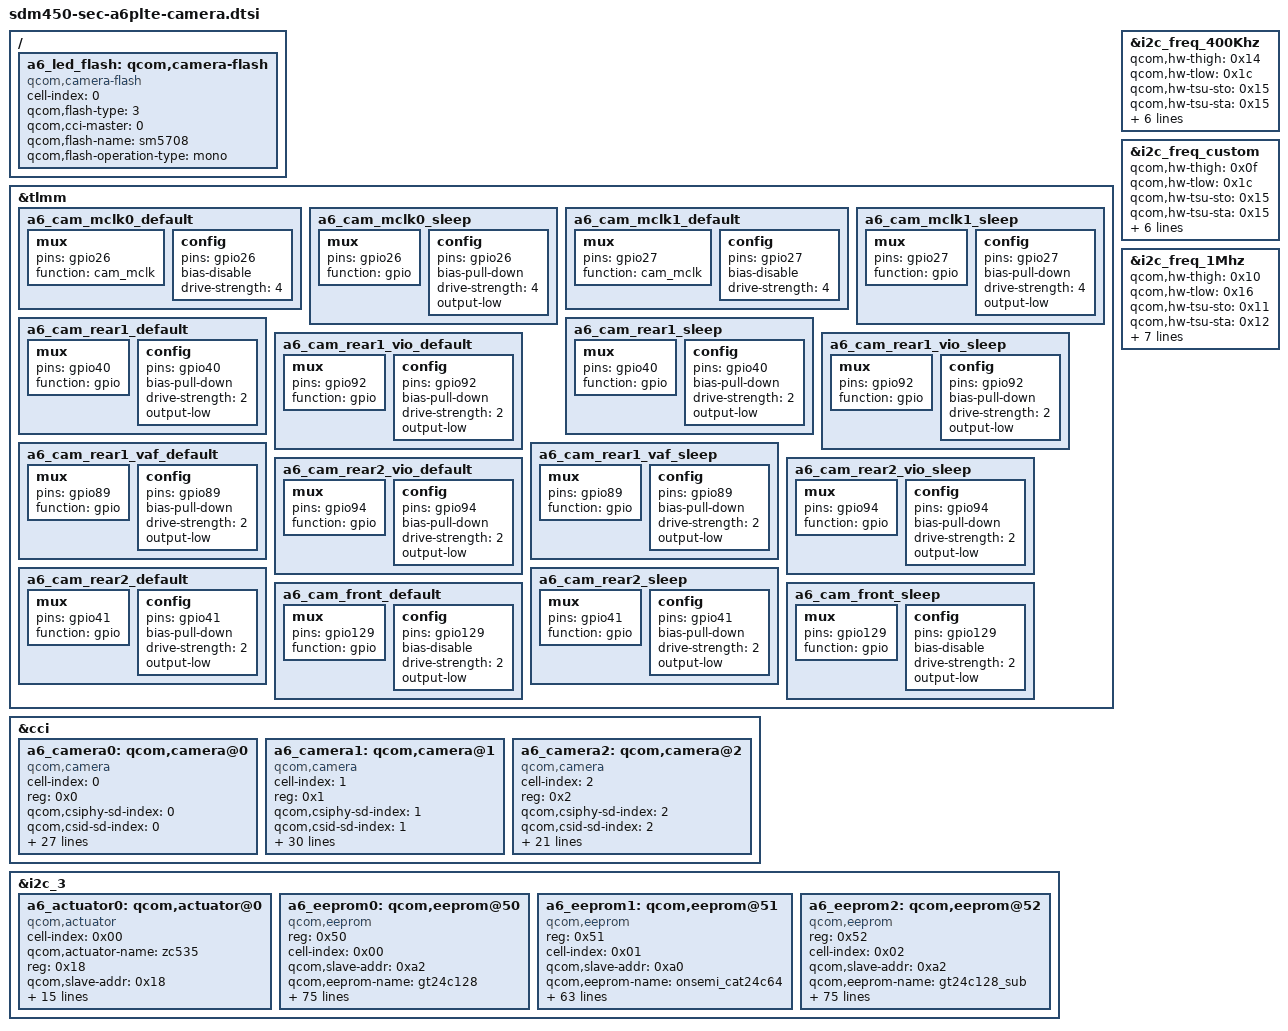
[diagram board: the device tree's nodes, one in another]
// Camera of the Samsung A6+ (rear S5K2P6SX, front S5K2X7SP, second rear SR556).
// Generated by scripts/gen-a6plte-camera-dtsi.py from the stock device tree.

&tlmm {
	a6_cam_mclk0_default: a6_cam_mclk0_default {
		mux {
			pins = "gpio26";
			function = "cam_mclk";
		};
		config {
			pins = "gpio26";
			bias-disable;
			drive-strength = <4>;
		};
	};

	a6_cam_mclk0_sleep: a6_cam_mclk0_sleep {
		mux {
			pins = "gpio26";
			function = "gpio";
		};
		config {
			pins = "gpio26";
			bias-pull-down;
			drive-strength = <4>;
			output-low;
		};
	};

	a6_cam_mclk1_default: a6_cam_mclk1_default {
		mux {
			pins = "gpio27";
			function = "cam_mclk";
		};
		config {
			pins = "gpio27";
			bias-disable;
			drive-strength = <4>;
		};
	};

	a6_cam_mclk1_sleep: a6_cam_mclk1_sleep {
		mux {
			pins = "gpio27";
			function = "gpio";
		};
		config {
			pins = "gpio27";
			bias-pull-down;
			drive-strength = <4>;
			output-low;
		};
	};

	a6_cam_rear1_default: a6_cam_rear1_default {
		mux {
			pins = "gpio40";
			function = "gpio";
		};
		config {
			pins = "gpio40";
			bias-pull-down;
			drive-strength = <2>;
			output-low;
		};
	};

	a6_cam_rear1_sleep: a6_cam_rear1_sleep {
		mux {
			pins = "gpio40";
			function = "gpio";
		};
		config {
			pins = "gpio40";
			bias-pull-down;
			drive-strength = <2>;
			output-low;
		};
	};

	a6_cam_rear1_vio_default: a6_cam_rear1_vio_default {
		mux {
			pins = "gpio92";
			function = "gpio";
		};
		config {
			pins = "gpio92";
			bias-pull-down;
			drive-strength = <2>;
			output-low;
		};
	};

	a6_cam_rear1_vio_sleep: a6_cam_rear1_vio_sleep {
		mux {
			pins = "gpio92";
			function = "gpio";
		};
		config {
			pins = "gpio92";
			bias-pull-down;
			drive-strength = <2>;
			output-low;
		};
	};

	a6_cam_rear1_vaf_default: a6_cam_rear1_vaf_default {
		mux {
			pins = "gpio89";
			function = "gpio";
		};
		config {
			pins = "gpio89";
			bias-pull-down;
			drive-strength = <2>;
			output-low;
		};
	};

	a6_cam_rear1_vaf_sleep: a6_cam_rear1_vaf_sleep {
		mux {
			pins = "gpio89";
			function = "gpio";
		};
		config {
			pins = "gpio89";
			bias-pull-down;
			drive-strength = <2>;
			output-low;
		};
	};

	a6_cam_rear2_vio_default: a6_cam_rear2_vio_default {
		mux {
			pins = "gpio94";
			function = "gpio";
		};
		config {
			pins = "gpio94";
			bias-pull-down;
			drive-strength = <2>;
			output-low;
		};
	};

	a6_cam_rear2_vio_sleep: a6_cam_rear2_vio_sleep {
		mux {
			pins = "gpio94";
			function = "gpio";
		};
		config {
			pins = "gpio94";
			bias-pull-down;
			drive-strength = <2>;
			output-low;
		};
	};

	a6_cam_rear2_default: a6_cam_rear2_default {
		mux {
			pins = "gpio41";
			function = "gpio";
		};
		config {
			pins = "gpio41";
			bias-pull-down;
			drive-strength = <2>;
			output-low;
		};
	};

	a6_cam_rear2_sleep: a6_cam_rear2_sleep {
		mux {
			pins = "gpio41";
			function = "gpio";
		};
		config {
			pins = "gpio41";
			bias-pull-down;
			drive-strength = <2>;
			output-low;
		};
	};

	a6_cam_front_default: a6_cam_front_default {
		mux {
			pins = "gpio129";
			function = "gpio";
		};
		config {
			pins = "gpio129";
			bias-disable;
			drive-strength = <2>;
			output-low;
		};
	};

	a6_cam_front_sleep: a6_cam_front_sleep {
		mux {
			pins = "gpio129";
			function = "gpio";
		};
		config {
			pins = "gpio129";
			bias-disable;
			drive-strength = <2>;
			output-low;
		};
	};

};

&cci {
	#address-cells = <1>;
	#size-cells = <0>;

	/* CCI timings of the stock DT (standard mode stays unused) */
}; /* cci */

&i2c_freq_400Khz {
	status = "ok";
	qcom,hw-thigh = <0x14>;
	qcom,hw-tlow = <0x1c>;
	qcom,hw-tsu-sto = <0x15>;
	qcom,hw-tsu-sta = <0x15>;
	qcom,hw-thd-dat = <0x0d>;
	qcom,hw-thd-sta = <0x12>;
	qcom,hw-tbuf = <0x20>;
	qcom,hw-scl-stretch-en = <0x00>;
	qcom,hw-trdhld = <0x06>;
	qcom,hw-tsp = <0x03>;
};

&i2c_freq_custom {
	status = "ok";
	qcom,hw-thigh = <0x0f>;
	qcom,hw-tlow = <0x1c>;
	qcom,hw-tsu-sto = <0x15>;
	qcom,hw-tsu-sta = <0x15>;
	qcom,hw-thd-dat = <0x0d>;
	qcom,hw-thd-sta = <0x12>;
	qcom,hw-tbuf = <0x19>;
	qcom,hw-scl-stretch-en = <0x01>;
	qcom,hw-trdhld = <0x06>;
	qcom,hw-tsp = <0x03>;
};

&i2c_freq_1Mhz {
	status = "ok";
	qcom,hw-thigh = <0x10>;
	qcom,hw-tlow = <0x16>;
	qcom,hw-tsu-sto = <0x11>;
	qcom,hw-tsu-sta = <0x12>;
	qcom,hw-thd-dat = <0x10>;
	qcom,hw-thd-sta = <0x0f>;
	qcom,hw-tbuf = <0x13>;
	qcom,hw-scl-stretch-en = <0x01>;
	qcom,hw-trdhld = <0x03>;
	qcom,hw-tsp = <0x03>;
	qcom,cci-clk-src = <0x23c3460>;
};

&i2c_3 {
	status = "ok";

	a6_actuator0: qcom,actuator@0 {
		compatible = "qcom,actuator";
		cell-index = <0x00>;
		qcom,actuator-name = "zc535";
		reg = <0x18>;
		qcom,slave-addr = <0x18>;
		gpios = <&tlmm 92 0>, <&tlmm 89 0>, <&expander 12 0>;
		qcom,gpio-vio = <0x00>;
		qcom,gpio-vaf = <0x01>;
		qcom,gpio-custom1 = <0x02>;
		qcom,gpio-req-tbl-num = <0x00 0x01 0x02>;
		qcom,gpio-req-tbl-flags = <0x00 0x00 0x00>;
		qcom,gpio-req-tbl-label = "CAM_VIO", "CAM_VAF", "CAM_CUSTOM1";
		qcom,sensor-position = <0x00>;
		qcom,cam-power-seq-type = "sensor_gpio", "sensor_gpio", "sensor_gpio";
		qcom,cam-power-seq-val = "sensor_gpio_vio", "sensor_gpio_vaf", "sensor_gpio_custom1";
		qcom,cam-power-seq-cfg-val = <0x01 0x01 0x01>;
		qcom,cam-power-seq-delay = <0x02 0x02 0x02>;
	};

	a6_eeprom0: qcom,eeprom@50 {
		compatible = "qcom,eeprom";
		reg = <0x50>;
		cell-index = <0x00>;
		qcom,slave-addr = <0xa2>;
		qcom,eeprom-name = "gt24c128";
		pinctrl-names = "cam_default", "cam_suspend";
		pinctrl-0 = <&a6_cam_rear1_vio_default &a6_cam_rear1_vaf_default>;
		pinctrl-1 = <&a6_cam_rear1_vio_sleep &a6_cam_rear1_vaf_sleep>;
		gpios = <&tlmm 92 0>, <&tlmm 89 0>, <&expander 12 0>;
		qcom,gpio-vio = <0x00>;
		qcom,gpio-vaf = <0x01>;
		qcom,gpio-custom1 = <0x02>;
		qcom,gpio-req-tbl-num = <0x00 0x01 0x02>;
		qcom,gpio-req-tbl-flags = <0x00 0x00 0x00>;
		qcom,gpio-req-tbl-label = "CAM_VIO", "CAM_VAF", "CAM_CUSTOM1";
		qcom,sensor-position = <0x00>;
		qcom,cam-power-seq-type = "sensor_gpio", "sensor_gpio", "sensor_gpio";
		qcom,cam-power-seq-val = "sensor_gpio_vio", "sensor_gpio_vaf", "sensor_gpio_custom1";
		qcom,cam-power-seq-cfg-val = <0x01 0x01 0x01>;
		qcom,cam-power-seq-delay = <0x02 0x02 0x02>;
		qcom,num-blocks = <0x12>;
		qcom,page0 = <0x00 0x00 0x00 0x00 0x00 0x00>;
		qcom,poll0 = <0x00 0x00 0x00 0x00 0x00 0x00>;
		qcom,mem0 = <0xfc 0x00 0x02 0x00 0x01 0x00>;
		qcom,page1 = <0x00 0x00 0x00 0x00 0x00 0x00>;
		qcom,poll1 = <0x00 0x00 0x00 0x00 0x00 0x00>;
		qcom,mem1 = <0x04 0xfc 0x02 0x00 0x01 0x00>;
		qcom,page2 = <0x00 0x00 0x00 0x00 0x00 0x00>;
		qcom,poll2 = <0x00 0x00 0x00 0x00 0x00 0x00>;
		qcom,mem2 = <0x708 0x100 0x02 0x00 0x01 0x00>;
		qcom,page3 = <0x00 0x00 0x00 0x00 0x00 0x00>;
		qcom,poll3 = <0x00 0x00 0x00 0x00 0x00 0x00>;
		qcom,mem3 = <0x04 0x808 0x02 0x00 0x01 0x00>;
		qcom,page4 = <0x00 0x00 0x00 0x00 0x00 0x00>;
		qcom,poll4 = <0x00 0x00 0x00 0x00 0x00 0x00>;
		qcom,mem4 = <0x50 0x80c 0x02 0x00 0x01 0x00>;
		qcom,page5 = <0x00 0x00 0x00 0x00 0x00 0x00>;
		qcom,poll5 = <0x00 0x00 0x00 0x00 0x00 0x00>;
		qcom,mem5 = <0x04 0x85c 0x02 0x00 0x01 0x00>;
		qcom,page6 = <0x00 0x00 0x00 0x00 0x00 0x00>;
		qcom,poll6 = <0x00 0x00 0x00 0x00 0x00 0x00>;
		qcom,mem6 = <0x30 0x860 0x02 0x00 0x01 0x00>;
		qcom,page7 = <0x00 0x00 0x00 0x00 0x00 0x00>;
		qcom,poll7 = <0x00 0x00 0x00 0x00 0x00 0x00>;
		qcom,mem7 = <0x04 0x890 0x02 0x00 0x01 0x00>;
		qcom,page8 = <0x00 0x00 0x00 0x00 0x00 0x00>;
		qcom,poll8 = <0x00 0x00 0x00 0x00 0x00 0x00>;
		qcom,mem8 = <0x38 0x894 0x02 0x00 0x01 0x00>;
		qcom,page9 = <0x00 0x00 0x00 0x00 0x00 0x00>;
		qcom,poll9 = <0x00 0x00 0x00 0x00 0x00 0x00>;
		qcom,mem9 = <0x04 0x8cc 0x02 0x00 0x01 0x00>;
		qcom,page10 = <0x00 0x00 0x00 0x00 0x00 0x00>;
		qcom,poll10 = <0x00 0x00 0x00 0x00 0x00 0x00>;
		qcom,mem10 = <0x708 0x900 0x02 0x00 0x01 0x00>;
		qcom,page11 = <0x00 0x00 0x00 0x00 0x00 0x00>;
		qcom,poll11 = <0x00 0x00 0x00 0x00 0x00 0x00>;
		qcom,mem11 = <0x04 0x1008 0x02 0x00 0x01 0x00>;
		qcom,page12 = <0x00 0x00 0x00 0x00 0x00 0x00>;
		qcom,poll12 = <0x00 0x00 0x00 0x00 0x00 0x00>;
		qcom,mem12 = <0x30 0x1060 0x02 0x00 0x01 0x00>;
		qcom,page13 = <0x00 0x00 0x00 0x00 0x00 0x00>;
		qcom,poll13 = <0x00 0x00 0x00 0x00 0x00 0x00>;
		qcom,mem13 = <0x04 0x1090 0x02 0x00 0x01 0x00>;
		qcom,page14 = <0x00 0x00 0x00 0x00 0x00 0x00>;
		qcom,poll14 = <0x00 0x00 0x00 0x00 0x00 0x00>;
		qcom,mem14 = <0x48 0x1094 0x02 0x00 0x01 0x00>;
		qcom,page15 = <0x00 0x00 0x00 0x00 0x00 0x00>;
		qcom,poll15 = <0x00 0x00 0x00 0x00 0x00 0x00>;
		qcom,mem15 = <0x04 0x10dc 0x02 0x00 0x01 0x00>;
		qcom,page16 = <0x00 0x00 0x00 0x00 0x00 0x00>;
		qcom,poll16 = <0x00 0x00 0x00 0x00 0x00 0x00>;
		qcom,mem16 = <0x80c 0x10e0 0x02 0x00 0x01 0x00>;
		qcom,page17 = <0x00 0x00 0x00 0x00 0x00 0x00>;
		qcom,poll17 = <0x00 0x00 0x00 0x00 0x00 0x00>;
		qcom,mem17 = <0x04 0x18ec 0x02 0x00 0x01 0x00>;
		qcom,total-size = <0x1900>;
	};

	a6_eeprom1: qcom,eeprom@51 {
		compatible = "qcom,eeprom";
		reg = <0x51>;
		cell-index = <0x01>;
		qcom,slave-addr = <0xa0>;
		qcom,eeprom-name = "onsemi_cat24c64";
		pinctrl-names = "cam_default", "cam_suspend";
		pinctrl-0 = <&a6_cam_rear2_vio_default &a6_cam_rear1_vio_default>;
		pinctrl-1 = <&a6_cam_rear2_vio_sleep &a6_cam_rear1_vio_sleep>;
		gpios = <&tlmm 94 0>, <&tlmm 92 0>, <&expander 12 0>;
		qcom,gpio-vio = <0x00>;
		qcom,gpio-custom1 = <0x01>;
		qcom,gpio-custom2 = <0x02>;
		qcom,gpio-req-tbl-num = <0x00 0x01 0x02>;
		qcom,gpio-req-tbl-flags = <0x00 0x00 0x00>;
		qcom,gpio-req-tbl-label = "CAM_CUSTOM1", "CAM_CUSTOM2", "CAM_VIO";
		qcom,sensor-position = <0x01>;
		qcom,cam-power-seq-type = "sensor_gpio", "sensor_gpio", "sensor_gpio";
		qcom,cam-power-seq-val = "sensor_gpio_custom1", "sensor_gpio_custom2", "sensor_gpio_vio";
		qcom,cam-power-seq-cfg-val = <0x01 0x01 0x01>;
		qcom,cam-power-seq-delay = <0x02 0x02 0x02>;
		qcom,num-blocks = <0x0e>;
		qcom,page0 = <0x00 0x00 0x00 0x00 0x00 0x00>;
		qcom,poll0 = <0x00 0x00 0x00 0x00 0x00 0x00>;
		qcom,mem0 = <0xe8 0x00 0x02 0x00 0x01 0x00>;
		qcom,page1 = <0x00 0x00 0x00 0x00 0x00 0x00>;
		qcom,poll1 = <0x00 0x00 0x00 0x00 0x00 0x00>;
		qcom,mem1 = <0x04 0xe8 0x02 0x00 0x01 0x00>;
		qcom,page2 = <0x00 0x00 0x00 0x00 0x00 0x00>;
		qcom,poll2 = <0x00 0x00 0x00 0x00 0x00 0x00>;
		qcom,mem2 = <0x708 0xec 0x02 0x00 0x01 0x00>;
		qcom,page3 = <0x00 0x00 0x00 0x00 0x00 0x00>;
		qcom,poll3 = <0x00 0x00 0x00 0x00 0x00 0x00>;
		qcom,mem3 = <0x04 0x7f4 0x02 0x00 0x01 0x00>;
		qcom,page4 = <0x00 0x00 0x00 0x00 0x00 0x00>;
		qcom,poll4 = <0x00 0x00 0x00 0x00 0x00 0x00>;
		qcom,mem4 = <0x50 0x7f8 0x02 0x00 0x01 0x00>;
		qcom,page5 = <0x00 0x00 0x00 0x00 0x00 0x00>;
		qcom,poll5 = <0x00 0x00 0x00 0x00 0x00 0x00>;
		qcom,mem5 = <0x04 0x848 0x02 0x00 0x01 0x00>;
		qcom,page6 = <0x00 0x00 0x00 0x00 0x00 0x00>;
		qcom,poll6 = <0x00 0x00 0x00 0x00 0x00 0x00>;
		qcom,mem6 = <0x30 0x84c 0x02 0x00 0x01 0x00>;
		qcom,page7 = <0x00 0x00 0x00 0x00 0x00 0x00>;
		qcom,poll7 = <0x00 0x00 0x00 0x00 0x00 0x00>;
		qcom,mem7 = <0x04 0x87c 0x02 0x00 0x01 0x00>;
		qcom,page8 = <0x00 0x00 0x00 0x00 0x00 0x00>;
		qcom,poll8 = <0x00 0x00 0x00 0x00 0x00 0x00>;
		qcom,mem8 = <0x24 0x880 0x02 0x00 0x01 0x00>;
		qcom,page9 = <0x00 0x00 0x00 0x00 0x00 0x00>;
		qcom,poll9 = <0x00 0x00 0x00 0x00 0x00 0x00>;
		qcom,mem9 = <0x04 0x8a4 0x02 0x00 0x01 0x00>;
		qcom,page10 = <0x00 0x00 0x00 0x00 0x00 0x00>;
		qcom,poll10 = <0x00 0x00 0x00 0x00 0x00 0x00>;
		qcom,mem10 = <0x6a 0x8a8 0x02 0x00 0x01 0x00>;
		qcom,page11 = <0x00 0x00 0x00 0x00 0x00 0x00>;
		qcom,poll11 = <0x00 0x00 0x00 0x00 0x00 0x00>;
		qcom,mem11 = <0x00 0x00 0x02 0x00 0x01 0x00>;
		qcom,page12 = <0x00 0x00 0x00 0x00 0x00 0x00>;
		qcom,poll12 = <0x00 0x00 0x00 0x00 0x00 0x00>;
		qcom,mem12 = <0xcfc 0x916 0x02 0x00 0x01 0x00>;
		qcom,page13 = <0x00 0x00 0x00 0x00 0x00 0x00>;
		qcom,poll13 = <0x00 0x00 0x00 0x00 0x00 0x00>;
		qcom,mem13 = <0x04 0x1612 0x02 0x00 0x01 0x00>;
		qcom,total-size = <0x1616>;
	};

	a6_eeprom2: qcom,eeprom@52 {
		compatible = "qcom,eeprom";
		reg = <0x52>;
		cell-index = <0x02>;
		qcom,slave-addr = <0xa2>;
		qcom,eeprom-name = "gt24c128_sub";
		pinctrl-names = "cam_default", "cam_suspend";
		pinctrl-0 = <&a6_cam_rear1_vio_default &a6_cam_rear1_vaf_default>;
		pinctrl-1 = <&a6_cam_rear1_vio_sleep &a6_cam_rear1_vaf_sleep>;
		gpios = <&tlmm 92 0>, <&tlmm 89 0>, <&expander 12 0>;
		qcom,gpio-vio = <0x00>;
		qcom,gpio-vaf = <0x01>;
		qcom,gpio-custom1 = <0x02>;
		qcom,gpio-req-tbl-num = <0x00 0x01 0x02>;
		qcom,gpio-req-tbl-flags = <0x00 0x00 0x00>;
		qcom,gpio-req-tbl-label = "CAM_VIO", "CAM_VAF", "CAM_CUSTOM1";
		qcom,sensor-position = <0x00>;
		qcom,cam-power-seq-type = "sensor_gpio", "sensor_gpio", "sensor_gpio";
		qcom,cam-power-seq-val = "sensor_gpio_vio", "sensor_gpio_vaf", "sensor_gpio_custom1";
		qcom,cam-power-seq-cfg-val = <0x01 0x01 0x01>;
		qcom,cam-power-seq-delay = <0x02 0x02 0x02>;
		qcom,num-blocks = <0x12>;
		qcom,page0 = <0x00 0x00 0x00 0x00 0x00 0x00>;
		qcom,poll0 = <0x00 0x00 0x00 0x00 0x00 0x00>;
		qcom,mem0 = <0xfc 0x00 0x02 0x00 0x01 0x00>;
		qcom,page1 = <0x00 0x00 0x00 0x00 0x00 0x00>;
		qcom,poll1 = <0x00 0x00 0x00 0x00 0x00 0x00>;
		qcom,mem1 = <0x04 0xfc 0x02 0x00 0x01 0x00>;
		qcom,page2 = <0x00 0x00 0x00 0x00 0x00 0x00>;
		qcom,poll2 = <0x00 0x00 0x00 0x00 0x00 0x00>;
		qcom,mem2 = <0x708 0x100 0x02 0x00 0x01 0x00>;
		qcom,page3 = <0x00 0x00 0x00 0x00 0x00 0x00>;
		qcom,poll3 = <0x00 0x00 0x00 0x00 0x00 0x00>;
		qcom,mem3 = <0x04 0x808 0x02 0x00 0x01 0x00>;
		qcom,page4 = <0x00 0x00 0x00 0x00 0x00 0x00>;
		qcom,poll4 = <0x00 0x00 0x00 0x00 0x00 0x00>;
		qcom,mem4 = <0x50 0x80c 0x02 0x00 0x01 0x00>;
		qcom,page5 = <0x00 0x00 0x00 0x00 0x00 0x00>;
		qcom,poll5 = <0x00 0x00 0x00 0x00 0x00 0x00>;
		qcom,mem5 = <0x04 0x85c 0x02 0x00 0x01 0x00>;
		qcom,page6 = <0x00 0x00 0x00 0x00 0x00 0x00>;
		qcom,poll6 = <0x00 0x00 0x00 0x00 0x00 0x00>;
		qcom,mem6 = <0x30 0x860 0x02 0x00 0x01 0x00>;
		qcom,page7 = <0x00 0x00 0x00 0x00 0x00 0x00>;
		qcom,poll7 = <0x00 0x00 0x00 0x00 0x00 0x00>;
		qcom,mem7 = <0x04 0x890 0x02 0x00 0x01 0x00>;
		qcom,page8 = <0x00 0x00 0x00 0x00 0x00 0x00>;
		qcom,poll8 = <0x00 0x00 0x00 0x00 0x00 0x00>;
		qcom,mem8 = <0x38 0x894 0x02 0x00 0x01 0x00>;
		qcom,page9 = <0x00 0x00 0x00 0x00 0x00 0x00>;
		qcom,poll9 = <0x00 0x00 0x00 0x00 0x00 0x00>;
		qcom,mem9 = <0x04 0x8cc 0x02 0x00 0x01 0x00>;
		qcom,page10 = <0x00 0x00 0x00 0x00 0x00 0x00>;
		qcom,poll10 = <0x00 0x00 0x00 0x00 0x00 0x00>;
		qcom,mem10 = <0x708 0x900 0x02 0x00 0x01 0x00>;
		qcom,page11 = <0x00 0x00 0x00 0x00 0x00 0x00>;
		qcom,poll11 = <0x00 0x00 0x00 0x00 0x00 0x00>;
		qcom,mem11 = <0x04 0x1008 0x02 0x00 0x01 0x00>;
		qcom,page12 = <0x00 0x00 0x00 0x00 0x00 0x00>;
		qcom,poll12 = <0x00 0x00 0x00 0x00 0x00 0x00>;
		qcom,mem12 = <0x30 0x1060 0x02 0x00 0x01 0x00>;
		qcom,page13 = <0x00 0x00 0x00 0x00 0x00 0x00>;
		qcom,poll13 = <0x00 0x00 0x00 0x00 0x00 0x00>;
		qcom,mem13 = <0x04 0x1090 0x02 0x00 0x01 0x00>;
		qcom,page14 = <0x00 0x00 0x00 0x00 0x00 0x00>;
		qcom,poll14 = <0x00 0x00 0x00 0x00 0x00 0x00>;
		qcom,mem14 = <0x48 0x1094 0x02 0x00 0x01 0x00>;
		qcom,page15 = <0x00 0x00 0x00 0x00 0x00 0x00>;
		qcom,poll15 = <0x00 0x00 0x00 0x00 0x00 0x00>;
		qcom,mem15 = <0x04 0x10dc 0x02 0x00 0x01 0x00>;
		qcom,page16 = <0x00 0x00 0x00 0x00 0x00 0x00>;
		qcom,poll16 = <0x00 0x00 0x00 0x00 0x00 0x00>;
		qcom,mem16 = <0x80c 0x10e0 0x02 0x00 0x01 0x00>;
		qcom,page17 = <0x00 0x00 0x00 0x00 0x00 0x00>;
		qcom,poll17 = <0x00 0x00 0x00 0x00 0x00 0x00>;
		qcom,mem17 = <0x04 0x18ec 0x02 0x00 0x01 0x00>;
		qcom,total-size = <0x1900>;
	};

};

/ {
	a6_led_flash: qcom,camera-flash {
		cell-index = <0>;
		compatible = "qcom,camera-flash";
		qcom,flash-type = <3>;
		qcom,cci-master = <0>;
		qcom,flash-name = "sm5708";
		qcom,flash-operation-type = "mono";
	};
};

&cci {
	a6_camera0: qcom,camera@0 {
		cell-index = <0>;
		compatible = "qcom,camera";
		reg = <0x0>;
		qcom,csiphy-sd-index = <0>;
		qcom,csid-sd-index = <0>;
		qcom,mount-angle = <90>;
		qcom,actuator-src = <&a6_actuator0>;
		qcom,led-flash-src = <&a6_led_flash>;
		qcom,eeprom-src = <&a6_eeprom0>;
		pinctrl-names = "cam_default", "cam_suspend";
		pinctrl-0 = <&a6_cam_mclk0_default &a6_cam_rear1_default
				&a6_cam_rear1_vio_default &a6_cam_rear1_vaf_default>;
		pinctrl-1 = <&a6_cam_mclk0_sleep &a6_cam_rear1_sleep
				&a6_cam_rear1_vio_sleep &a6_cam_rear1_vaf_sleep>;
		gpios = <&tlmm 26 0>, <&tlmm 40 0>, <&tlmm 92 0>, <&tlmm 89 0>,
			<&expander 12 0>;
		qcom,gpio-reset = <1>;
		qcom,gpio-vio = <2>;
		qcom,gpio-vaf = <3>;
		qcom,gpio-custom1 = <4>;
		qcom,gpio-req-tbl-num = <0 1 2 3 4>;
		qcom,gpio-req-tbl-flags = <1 0 0 0 0>;
		qcom,gpio-req-tbl-label = "CAMIF_MCLK0", "CAM_RESET0", "CAM_VIO",
					  "CAM_VAF", "CAM_CUSTOM1";
		qcom,sensor-position = <0>;
		qcom,sensor-mode = <0>;
		qcom,cci-master = <1>;
		status = "ok";
		clocks = <&clock_gcc clk_mclk0_clk_src>,
			 <&clock_gcc clk_gcc_camss_mclk0_clk>;
		clock-names = "cam_src_clk", "cam_clk";
		qcom,clock-rates = <24000000 0>;
	};

	a6_camera1: qcom,camera@1 {
		cell-index = <1>;
		compatible = "qcom,camera";
		reg = <0x1>;
		qcom,csiphy-sd-index = <1>;
		qcom,csid-sd-index = <1>;
		qcom,mount-angle = <270>;
		qcom,led-flash-src = <&a6_led_flash>;
		qcom,eeprom-src = <&a6_eeprom1>;
		cam_vdig-supply = <&pm8953_l23>;
		qcom,cam-vreg-name = "cam_vdig";
		qcom,cam-vreg-type = <0>;
		qcom,cam-vreg-min-voltage = <1050000>;
		qcom,cam-vreg-max-voltage = <1050000>;
		qcom,cam-vreg-op-mode = <1050000>;
		pinctrl-names = "cam_default", "cam_suspend";
		pinctrl-0 = <&a6_cam_mclk1_default &a6_cam_front_default
				&a6_cam_rear2_vio_default>;
		pinctrl-1 = <&a6_cam_mclk1_sleep &a6_cam_front_sleep
				&a6_cam_rear2_vio_sleep>;
		gpios = <&tlmm 27 0>, <&tlmm 129 0>, <&expander 12 0>,
			<&expander 13 0>, <&tlmm 94 0>;
		qcom,gpio-reset = <1>;
		qcom,gpio-vio = <2>;
		qcom,gpio-vana = <3>;
		qcom,gpio-custom1 = <4>;
		qcom,gpio-req-tbl-num = <0 1 2 3 4>;
		qcom,gpio-req-tbl-flags = <1 0 0 0 0>;
		qcom,gpio-req-tbl-label = "CAMIF_MCLK1", "CAM_RESET1", "CAM_VIO",
					  "CAM_VANA", "CAM_CUSTOM1";
		qcom,sensor-position = <1>;
		qcom,sensor-mode = <0>;
		qcom,cci-master = <0>;
		status = "ok";
		clocks = <&clock_gcc clk_mclk1_clk_src>,
			 <&clock_gcc clk_gcc_camss_mclk1_clk>;
		clock-names = "cam_src_clk", "cam_clk";
		qcom,clock-rates = <24000000 0>;
	};

	a6_camera2: qcom,camera@2 {
		cell-index = <2>;
		compatible = "qcom,camera";
		reg = <0x2>;
		qcom,csiphy-sd-index = <2>;
		qcom,csid-sd-index = <2>;
		qcom,mount-angle = <90>;
		qcom,eeprom-src = <&a6_eeprom2>;
		pinctrl-names = "cam_default", "cam_suspend";
		pinctrl-0 = <&a6_cam_mclk0_default &a6_cam_rear2_default
				&a6_cam_rear2_vio_default>;
		pinctrl-1 = <&a6_cam_mclk0_sleep &a6_cam_rear2_sleep
				&a6_cam_rear2_vio_sleep>;
		gpios = <&tlmm 26 0>, <&tlmm 41 0>, <&tlmm 94 0>,
			<&expander 12 0>;
		qcom,gpio-reset = <1>;
		qcom,gpio-vio = <2>;
		qcom,gpio-custom1 = <3>;
		qcom,gpio-req-tbl-num = <0 1 2 3>;
		qcom,gpio-req-tbl-flags = <1 0 0 0>;
		qcom,gpio-req-tbl-label = "CAMIF_MCLK0", "CAM_RESET2", "CAM_VIO",
					  "CAM_CUSTOM1";
		qcom,sensor-position = <0>;
		qcom,sensor-mode = <0>;
		qcom,cci-master = <0>;
		status = "ok";
		clocks = <&clock_gcc clk_mclk0_clk_src>,
			 <&clock_gcc clk_gcc_camss_mclk0_clk>;
		clock-names = "cam_src_clk", "cam_clk";
		qcom,clock-rates = <24000000 0>;
	};
};

